# SPC1169 register map
File version: 2022071043481212
CPU: cm4 r1p0, little endian, no MPU, FPU, 4 interrupt priority bits
Registers are 32-bit, read-write, reset 0x0 unless marked. A register's access mark holds for its fields unless they carry their own. Offsets are from the block's base; [hi:lo] are bit positions; 'fields as' and 'values as' point back to an identical list.

## I2C
Base 0x40003500
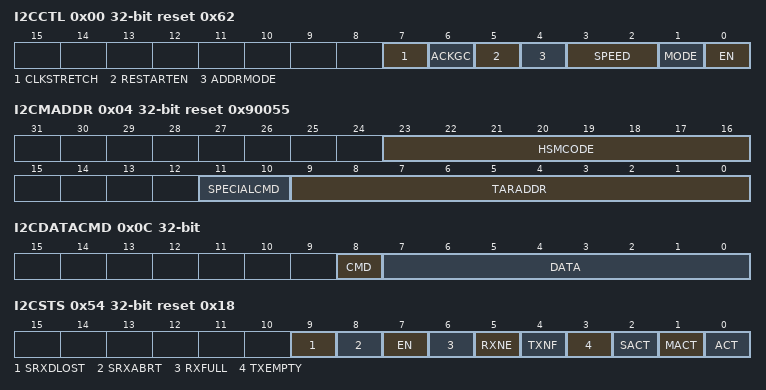
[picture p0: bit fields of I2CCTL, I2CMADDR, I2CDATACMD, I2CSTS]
0x00 I2CCTL reset 0x62 — I2C Control Register
  [7] CLKSTRETCH — Clock stretch on RX FIFO full
    0=DISABLE; 1=ENABLE
  [6] ACKGC — Respond upon General Call. This bit is applicable only for slave mode
    0=NACK (Responds General Call with an NACK); 1=ACK (Responds General Call with an ACK)
  [5] RESTARTEN — Determines whether RESTART conditions may be sent when acting as a master. Some older slaves do not support handling RESTART conditions; however, RESTART conditions are used in several I2C operations. When RESTART is disabled, the master is prohibited from performing the following functions: - Change direction within a transfer (split) - Send a START BYTE - High-speed mode operation - Combined format transfers in 7-bit addressing modes - Read operation with a 10-bit address - Send multiple bytes per transfer By replacing RESTART condition followed by a STOP and a subsequent START condition, split operations are broken down into multiple I2C transfers. If the above operations are performed, it will result in setting bit 6 (TXABRT) of the I2CRAWIF register.
    0=DISABLE; 1=ENABLE
  [4] ADDRMODE — Addressing mode
    0=7BIT_ADDR (7-bit addressing. The I2C ignores transactions that involve 10-bit addressing; for 7-bit addressing, only the lower 7 bits of the I2CSLVADDR register are compared.); 1=10BIT_ADDR (10-bit addressing. The I2C responds to only 10-bit addressing transfers that match the full 10 bits of the I2CSLVADDR register.)
  [3:2] SPEED — Speed in master mode
    0=STANDARD (Standard mode (100 kbit/s)); 1=FAST (Fast mode (400 kbit/s)); 2=HIGH (High speed mode (3.4 Mbit/s))
  [1] MODE — I2C mode
    0=SLAVE (Set I2C in slave mode); 1=MASTER (Set I2C in master mode)
  [0] EN — I2C enable (There are two I2C clock delay when enable or disable the I2C). When I2C is disabled, the following occurs: - The TX FIFO and RX FIFO get flushed. - Status bits in the I2CIF register are still active until I2C goes into IDLE state. - If the module is transmitting, it stops as well as deletes the contents of the transmit FIFO after the current transfer is complete. - If the module is receiving, the I2C stops the current transfer at the end of the current byte and does not acknowledge the transfer.
    0=DISABLE (Disable I2C (Hold FIFOs in an erased state). Software can disable I2C while it is active. However, it is important that care be taken to ensure that i2c is disabled properly.); 1=ENABLE (Enable I2C)
0x04 I2CMADDR reset 0x90055 — I2C Master Address Register
  [23:16] HSMCODE — 8-bit high-speed mode master code in format of (0x00001xxx). This register can be written only when the I2C interface is disabled (I2CCTL_EN=0) and the value to write is in valid format (00001xxx). Writes at other times have no effect.
  [11:10] SPECIALCMD — Special command
    0=DISABLE (Disable special command); 2=GENERAL_CALL (General Call. After issuing a General Call, only writes may be performed. Attempting to issue a read command results in setting bit 6 (TXABRT) of the I2CRAWIF register. The I2C remains in General Call mode until the SPECIAL bit is cleared); 3=START_BYTE
  [9:0] TARADDR — Target address for any master transaction. These bits are ignored for issuing a General Call. To generate a START BYTE, the CPU needs to write only once into these bits. It should not be the same as I2CSLVADDR.
0x08 I2CSADDR reset 0x55 — I2C Slave Address Register
  [9:0] VAL — Slave address when I2C acts as a slave. This register can be written only when I2CCTL_EN=0. Writes at other times have no effect. Note: The default values cannot be any of the reserved address locations: that is, 0x00 to 0x07, or 0x78 to 0x7f. The correct operation of the device is not guaranteed if you program the I2CSLVADDR or I2CMASTERADDR to a reserved value.
0x0C I2CDATACMD — I2C Data and Command Register
  [8] CMD — Read or write control
    0=WRITE; 1=READ
  [7:0] DATA — Data transmitted or received on the I2C bus. A write to the register sets the data to be transmitted. A read to the register gets the received data.
0x10 I2CSSLCNT reset 0x24C — Standard Speed I2C Clock SCL Low Count Register
  [15:0] VAL — Duration for SCL low in standard speed mode. i.e. SCL is low for I2CSSLCNT clock cycles. The minimum valid value is 4. Write a value below 4 will be reset as 4 by the hardware. This register can be written only when I2CCTL_EN=0. Writes at other times have no effect.
0x14 I2CSSHCNT reset 0x1F4 — Standard Speed I2C Clock SCL High Count Register
  [15:0] VAL — Duration for SCL high in standard speed mode. i.e. SCL is high for I2CSSHCNT clock cycles. The minimum valid value is 5. Write a value below 5 will be reset as 5 by the hardware. This register can be written only when I2CCTL_EN=0. Writes at other times have no effect.
0x18 I2CFSLCNT reset 0xA3 — Fast Speed I2C Clock SCL Low Count Register
  [15:0] VAL — Duration for SCL low in fast speed mode. i.e. SCL is low for I2CFSLCNT clock cycles. The minimum valid value is 4. Write a value below 4 will be reset as 4 by the hardware. This register can be written only when I2CCTL_EN=0. Writes at other times have no effect.
0x1C I2CFSHCNT reset 0x4B — Fast Speed I2C Clock SCL High Count Register
  [15:0] VAL — Duration for SCL high in fast speed mode. i.e. SCL is high for I2CFSHCNT clock cycles. The minimum valid value is 5. Write a value below 5 will be reset as 5 by the hardware. This register can be written only when I2CCTL_EN=0. Writes at other times have no effect.
0x20 I2CHSLCNT reset 0x14 — High Speed I2C Clock SCL Low Count Register
  [15:0] VAL — Duration for SCL low in high speed mode. i.e. SCL is low for I2CHSLCNT clock cycles. The minimum valid value is 4. Write a value below 4 will be reset as 4 by the hardware. This register can be written only when I2CCTL_EN=0. Writes at other times have no effect.
0x24 I2CHSHCNT reset 0x8 — High Speed I2C Clock SCL High Count Register
  [15:0] VAL — Duration for SCL high in high speed mode. i.e. SCL is high for I2CHSHCNT clock cycles. The minimum valid value is 1. Write a 0 will be reset as 1 by the hardware. This register can be written only when I2CCTL_EN=0. Writes at other times have no effect.
0x28 I2CFSSPKLEN reset 0x6 — Fast Speed I2C Spike Suppresion Limit Register
  [7:0] VAL — Duration in fast speed mode of the longest spike in the SCL or SDA lines that are filtered out by the spike suppression logic. The minimum value is 1 and write a 0 will be reset as 1 by the hardware. This register can be written only when I2CCTL_EN=0. Writes at other times have no effect.
0x2C I2CHSSPKLEN reset 0x2 — High Speed I2C Spike Suppresion Limit Register
  [7:0] VAL — Duration in high speed mode of the longest spike in the SCL or SDA lines that are filtered out by the spike suppression logic. The minimum value is 1 and write a 0 will be reset as 1 by the hardware. This register can be written only when I2CCTL_EN=0. Writes at other times have no effect.
0x30 I2CSDASETUP reset 0x64 — I2C SDA Setup Time Register
  [7:0] VAL — Configure SDA setup time as VAL CLK_I2C cycles i.e. If the required setup delay is 1000ns, then for an CLK_I2C frequency of 10 MHz, this register is recommended to be programmed as 11. The minimum value is 2 and write a value below 2 will be reset as 2 by the hardware. This register can be written only when I2CCTL_EN=0. Writes at other times have no effect.
0x34 I2CSDAHOLD reset 0x1 — I2C SDA Hold Time Register
  [15:0] VAL — Configure SDA hold time as VAL CLK_I2C cycles i.e. If the required hold delay is 1000ns, then for an CLK_I2C frequency of 10 MHz, this register is recommended to be programmed as 11. This register can be written only when I2CCTL_EN=0. Writes at other times have no effect.
0x38 I2CTXLVL ro — I2C Transmit FIFO Level Register
  [4:0] VAL — Number of valid data entries in the transmit FIFO.
0x3C I2CRXLVL ro — I2C Receive FIFO Level Register
  [4:0] VAL — Number of valid data entries in the receive FIFO.
0x40 I2CTXTH — I2C Transmit FIFO Threshold Register
  [3:0] VAL — Transmit FIFO threshold level to trigger the TFEMPTY interrupt
0x44 I2CRXTH — I2C Receive FIFO Threshold Register
  [3:0] VAL — Receive FIFO threshold level to trigger the RFFULL interrupt
0x54 I2CSTS ro reset 0x18 — I2C Status Register
  [9] SRXDLOST — Slave received data lost upon disable I2C
    0=NOT_OCCUR (Slave receiver operation is done before I2CENABLE is changed from 1 to 0); 1=OCCUR (Slave receiver operation is aborted with at least one data byte received from an I2C transfer when I2CENABLE is changed from 1 to 0)
  [8] SRXABRT — Slave disabled while it is busy
    0=NOT_OCCUR (I2CENABLE is stable during slave operation); 1=OCCUR (I2CENABLE is changed from 1 to 0 when I2C slave is receiving from a remote mater on (a) The address byte of the slave transmitter (b) The address and data bytes of the slave receiver)
  [7] EN — I2C enabled status
    0=DISABLE (I2C is deemed completely inactive. SLVRDLOST and SLVDISONBUSY bits can be read safely); 1=ENABLE (I2C is deemed to be in an enabled state)
  [6] RXFULL — Receive FIFO completely full
    0=NOT_FULL (Receive FIFO contains empty location); 1=FULL (Receive FIFO is completely full)
  [5] RXNE — Receive FIFO not empty (so can read data from it)
    0=EMPTY (Receive FIFO is empty); 1=NOT_EMPTY (Receive FIFO contains one or more entries)
  [4] TXNF — Transmit FIFO not full (so can write data to it)
    0=FULL (Transmit FIFO is full); 1=NOT_FULL (Transmit FIFO contains empty locations)
  [3] TXEMPTY — Transmit FIFO completely empty
    0=NOT_EMPTY (Transmit FIFO contains one or more entries); 1=EMPTY (Transmit FIFO is empty)
  [2] SACT — Slave FSM (Finite State Machine) activity status
    0=IDLE (Slave FSM is in IDLE state (Inactive)); 1=ACTIVE (Slave FSM is not in IDLE state (Active))
  [1] MACT — Master FSM activity status
    0=IDLE (Master FSM is in IDLE state (Inactive)); 1=ACTIVE (Master FSM is not in IDLE state (Active))
  [0] ACT — I2C activity status (Logic OR of SACT and MACT)
    0=IDLE (Both master and slave FSM are in idle state); 1=ACTIVE (Either master or slave FSM is active)
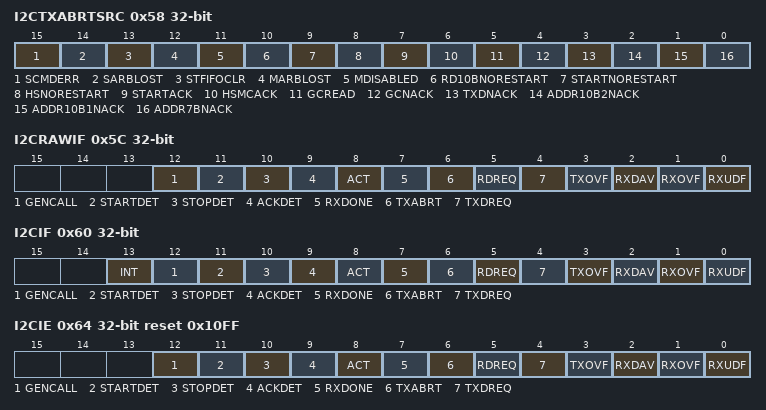
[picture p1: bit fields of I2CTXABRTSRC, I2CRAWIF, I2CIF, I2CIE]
0x58 I2CTXABRTSRC ro — I2C Transmit Abort Source Register
  [all] fields
    0=NOT_OCCUR; 1=OCCUR
  [15] SCMDERR — Role of I2C: Slave transmitter. This bit is set when the processor side responds to a slave mode request for data to be transmitted to a remote master and user writes a 1 in CMD (bit 8) of I2CDATACMD register.
  [14] SARBLOST — Role of I2C: Slave transmitter. This bit is set when slave lost the bus while transmitting data to a remote master. I2CTXABRTSRC.MARBLOST is set at the same time. Note: Even though the slave never 'owns' the bus, something could go wrong on the bus. This is a failsafe check. For instance, during a data transmission at the low-to-high transition of SCL, if what is on the data bus is not what is supposed to be transmitted, then I2C no longer own the bus.
  [13] STFIFOCLR — Role of I2C: Slave transmitter. This bis is set when slave has received a read command and some data exists in the TX FIFO so the slave issues a TXABRT interrupt to clear old data in TX FIFO.
  [12] MARBLOST — Role of I2C: Master/slave transmitter. This bit is set when master has lost arbitration, or if I2CTXABRTSRC.SARBLOST is also set, then the slave transmitter has lost arbitration.
  [11] MDISABLED — Role of I2C: Master transmitter/receiver. This bit is set when user tries to initiate a master operation with the master mode is disabled.
  [10] RD10BNORESTART — Role of I2C: Master receiver. This bit is set when the restart is disabled (I2CCTL.RESTARTEN=0) and the master sends a read command in 10-bit addressing mode.
  [9] STARTNORESTART — Role of I2C: Master transmitter/receiver. This bit is set when the restart is disabled (I2CCTL.RESTARTEN=0) and the user is trying to send a START Byte. Follow configurations below to avoid this error (1) I2CCTL.RESTARTEN=1 (2) I2CMASTERADDR.SPECIAL=0 or I2CMASTERADDR.GCORSTART=0. Otherwise, this bit is set again at next clock after it is cleared by writing a 1 to I2CIC_TXABRT
  [8] HSNORESTART — Role of I2C: Master transmitter/receiver. This bit is set when the restart is disabled (I2CCTL.RESTARTEN=0) and the user is trying to use the master to transfer data in high speed mode.
  [7] STARTACK — Role of I2C: Master transmitter/receiver. This bit is set when master has sent a START Byte and the START Byte was acknowledged (wrong behavior).
  [6] HSMCACK — Role of I2C: Master transmitter/receiver. This bit is set when master is in high speed mode and the high speed master code was acknowledged (wrong behavior).
  [5] GCREAD — Role of I2C: Master transmitter. This bit is set when master sent a General Call but the user programmed the byte following the General Call to be a read from the bus (I2CDATACMD_CMD=1).
  [4] GCNACK — Role of I2C: Master transmitter. This bit is set when master sent a General Call and no slave on the bus acknowledged the General Call.
  [3] TXDNACK — Role of I2C: Master transmitter. This bit is set when master has received an acknowledgement for the address, but when it sent data byte(s) following the address, it did not receive an acknowledge from the remote slave(s).
  [2] ADDR10B2NACK — Role of I2C: Master transmitter/receiver. This bit is set when master is in 10-bit address mode and the second address byte of the 10-bit address was not acknowledged by any slave.
  [1] ADDR10B1NACK — Role of I2C: Master transmitter/receiver. This bit is set when master is in 10-bit address mode and the first 10-bit address byte was not acknowledged by any slave.
  [0] ADDR7BNACK — Role of I2C: Master transmitter/receiver. This bit is set when master is in 7-bit addressing mode and the address sent was not acknowledged by any slave.
0x5C I2CRAWIF ro — I2C Raw Interrupt Flag Register
  [12] GENCALL — General Call address received and acknowledged flag
    0=NOT_OCCUR; 1=OCCUR (Occurred)
  [11] STARTDET — START or RESTART condition flag
    0=NOT_OCCUR (Condition is not detected); 1=OCCUR (Condition is detected)
  [10] STOPDET — STOP condition flag
    values as STARTDET
  [9] ACKDET — Latched flag for detected ACK from external receiver
    0=NOT_OCCUR (ACK is not detected); 1=OCCUR (ACK is detected)
  [8] ACT — Latched I2C activity status flag
    0=NOT_OCCUR (There is no activity detected on I2C interface); 1=OCCUR (Activity has been detected on I2C interface)
  [7] RXDONE — Flag to indicate external master receive is done when I2C acts as a slave transmitter
    0=NOT_OCCUR (Slave transmission is acknowledged by the other master, which continues data receiving.); 1=OCCUR (Slave transmission is not acknowledge by the other master, which finishes the data receiving)
  [6] TXABRT — Latched transmission abort flag
    0=NOT_OCCUR (No transmission abortion occurred); 1=OCCUR (Transimission aborted and TX FIFO remains in flushed state until write a 1 to I2CIC_TXABRT)
  [5] RDREQ — Latched external master read request flag when the I2C is acting as a slave
    0=NOT_OCCUR (No read request is received from another master); 1=OCCUR (Read request was received from another master. The processor must respond to this interrupt and then write the requested data to the I2CDATACMD register.)
  [4] TXDREQ — Flag to indicate there is not enough data in the transmit FIFO and request for more data
    0=NOT_OCCUR (I2CTXLVL>I2CTXTH); 1=OCCUR (I2CTXLVL<=I2CTXTH. This bit is self-cleared when I2CTXLVL>I2CTXTH)
  [3] TXOVF — Flag to indicate an attempt to write I2CDATACMD register when transmit FIFO is full
    0=NOT_OCCUR (Transmit FIFO does not overflow); 1=OCCUR (Transmit FIFO overflows)
  [2] RXDAV — Flag to indicate there is enough data in the receive FIFO and available for read
    0=NOT_OCCUR (I2CRXLVL<= I2CRXTH); 1=OCCUR (I2CRXLVL>I2CRXTH. This bit is self-cleared when I2CRXLVL<=I2CRXTH)
  [1] RXOVF — Flag to indicate the receive FIFO is completely filled to 16 and an additional byte is received from an external I2C device. The I2C acknowledges this, but any data bytes received after the FIFO is full are lost.
    0=NOT_OCCUR (Receive FIFO does not overflow); 1=OCCUR (Receive FIFO overflows)
  [0] RXUDF — Flag to indicate the processor attempts to read the receive FIFO via I2CDATACMD register when it is empty
    0=NOT_OCCUR (Receive FIFO does not underflow); 1=OCCUR (Receive FIFO underflows)
0x60 I2CIF ro — I2C Interrupt Flag Register
  [13] INT — Global interrupt flag
    0=NOT_OCCUR; 1=OCCUR (Occurred)
  [12] GENCALL — General Call address received and acknowledged flag
    0=NOT_OCCUR; 1=OCCUR (Occurred)
  [11] STARTDET — START or RESTART condition flag
    values as I2CRAWIF.STARTDET
  [10] STOPDET — STOP condition flag
    values as I2CRAWIF.STARTDET
  [9] ACKDET — Latched flag for detected ACK from external receiver
    0=NOT_OCCUR (ACK is not detected); 1=OCCUR (ACK is detected)
  [8] ACT — Latched I2C activity status flag
    values as I2CRAWIF.ACT
  [7] RXDONE — Flag to indicate external master receive is done when I2C acts as a slave transmitter
    values as I2CRAWIF.RXDONE
  [6] TXABRT — Latched transmission abort flag
    values as I2CRAWIF.TXABRT
  [5] RDREQ — Latched external master read request flag when the I2C is acting as a slave
    values as I2CRAWIF.RDREQ
  [4] TXDREQ — Flag to indicate there is not enough data in the transmit FIFO and request for more data
    values as I2CRAWIF.TXDREQ
  [3] TXOVF — Flag to indicate an attempt to write I2CDATACMD register when transmit FIFO is full
    values as I2CRAWIF.TXOVF
  [2] RXDAV — Flag to indicate there is enough data in the receive FIFO and available for read
    values as I2CRAWIF.RXDAV
  [1] RXOVF — Flag to indicate the receive FIFO is completely filled to 16 and an additional byte is received from an external I2C device. The I2C acknowledges this, but any data bytes received after the FIFO is full are lost.
    values as I2CRAWIF.RXOVF
  [0] RXUDF — Flag to indicate the processor attempts to read the receive FIFO via I2CDATACMD register when it is empty
    values as I2CRAWIF.RXUDF
0x64 I2CIE reset 0x10FF — I2C Interrupt Enable Register
  [12] GENCALL — Enable/disable GENCALL interrupt
    0=DISABLE (Disable GENCALL interrupt); 1=ENABLE (Enable GENCALL interrupt)
  [11] STARTDET — Enable/disable STARTDET interrupt
    0=DISABLE (Disable STARTDET interrupt); 1=ENABLE (Enable STARTDET interrupt)
  [10] STOPDET — Enable/disable STOPDET interrupt
    0=DISABLE (Disable STOPDET interrupt); 1=ENABLE (Enable STOPDET interrupt)
  [9] ACKDET — Enable/disable ACKDET interrupt
    0=DISABLE (Disable ACKDET interrupt); 1=ENABLE (Enable ACKDET interrupt)
  [8] ACT — Enable/disable ACTIVITY interrupt
    0=DISABLE (Disable ACTIVITY interrupt); 1=ENABLE (Enable ACTIVITY interrupt)
  [7] RXDONE — Enable/disable RXDONE interrupt
    0=DISABLE (Disable RXDONE interrupt); 1=ENABLE (Enable RXDONE interrupt)
  [6] TXABRT — Enable/disable TXABRT interrupt
    0=DISABLE (Disable TXABRT interrupt); 1=ENABLE (Enable TXABRT interrupt)
  [5] RDREQ — Enable/disable RDREQ interrupt
    0=DISABLE (Disable RDREQ interrupt); 1=ENABLE (Enable RDREQ interrupt)
  [4] TXDREQ — Enable/disable TXDREQ interrupt
    0=DISABLE (Disable TXDREQ interrupt); 1=ENABLE (Enable TXDREQ interrupt)
  [3] TXOVF — Enable/disable TXOVF interrupt
    0=DISABLE (Disable TXOVF interrupt); 1=ENABLE (Enable TXOVF interrupt)
  [2] RXDAV — Enable/disable RXDAV interrupt
    0=DISABLE (Disable RXDAV interrupt); 1=ENABLE (Enable RXDAV interrupt)
  [1] RXOVF — Enable/disable RXOVF interrupt
    0=DISABLE (Disable RXOVF interrupt); 1=ENABLE (Enable RXOVF interrupt)
  [0] RXUDF — Enable/disable RXUDF interrupt
    0=DISABLE (Disable RXUDF interrupt); 1=ENABLE (Enable RXUDF interrupt)
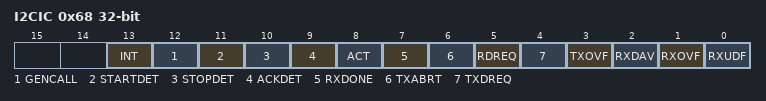
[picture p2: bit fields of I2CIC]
0x68 I2CIC — I2C Interrupt Enable Register
  [all] fields
    0=NO_EFFECT (Write a 0 has no effect and always reads back 0); 1=CLEAR (Write a 1 clears the interupt flag. This bit is self-cleared to 0)
  [13] INT — Clear global combined interrupt
  [12] GENCALL — Clear GENCALL interrupt
  [11] STARTDET — Clear STARTDET interrupt
  [10] STOPDET — Clear STOPDET interrupt
  [9] ACKDET — Clear ACKDET interrupt
  [8] ACT — Clear ACTIVITY interrupt
  [7] RXDONE — Clear RXDONE interrupt
  [6] TXABRT — Clear TXABRT interrupt
  [5] RDREQ — Clear RDREQ interrupt
  [4] TXDREQ — Clear TXDREQ interrupt
  [3] TXOVF — Clear TXOVF interrupt
  [2] RXDAV — Clear RXDAV interrupt
  [1] RXOVF — Clear RXOVF interrupt
  [0] RXUDF — Clear RXUDF interrupt
0x6C I2CREGKEY reset 0x1ACCE551 — I2C Register Write-Allow Key Register
  [31:0] KEY — Write 0x1ACCE551 to unlock protected I2C registers. The 28 MSBs of this register cannot be 0x5555555
